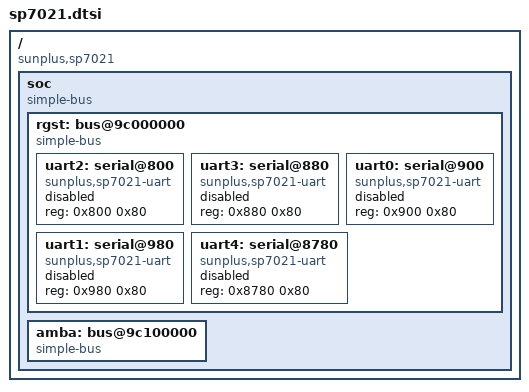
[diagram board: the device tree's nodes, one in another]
// SPDX-License-Identifier: GPL-2.0-or-later OR BSD-2-Clause
/*
 * Copyright (c) 2020 Andreas Färber
 */

/ {
	compatible = "sunplus,sp7021";
	#address-cells = <1>;
	#size-cells = <1>;

	soc {
		compatible = "simple-bus";
		#address-cells = <1>;
		#size-cells = <1>;
		ranges = <0x20000000 0x20000000 0xe0000000>;

		rgst: bus@9c000000 {
			compatible = "simple-bus";
			#address-cells = <1>;
			#size-cells = <1>;
			ranges = <0x0 0x9c000000 0x00100000>;

			uart2: serial@800 {
				compatible = "sunplus,sp7021-uart";
				reg = <0x800 0x80>;
				status = "disabled";
			};

			uart3: serial@880 {
				compatible = "sunplus,sp7021-uart";
				reg = <0x880 0x80>;
				status = "disabled";
			};

			uart0: serial@900 {
				compatible = "sunplus,sp7021-uart";
				reg = <0x900 0x80>;
				status = "disabled";
			};

			uart1: serial@980 {
				compatible = "sunplus,sp7021-uart";
				reg = <0x980 0x80>;
				status = "disabled";
			};

			uart4: serial@8780 {
				compatible = "sunplus,sp7021-uart";
				reg = <0x8780 0x80>;
				status = "disabled";
			};
		};

		amba: bus@9c100000 {
			compatible = "simple-bus";
			#address-cells = <1>;
			#size-cells = <1>;
			ranges = <0x0 0x9c100000 0x01ef0000>;
		};
	};
};
